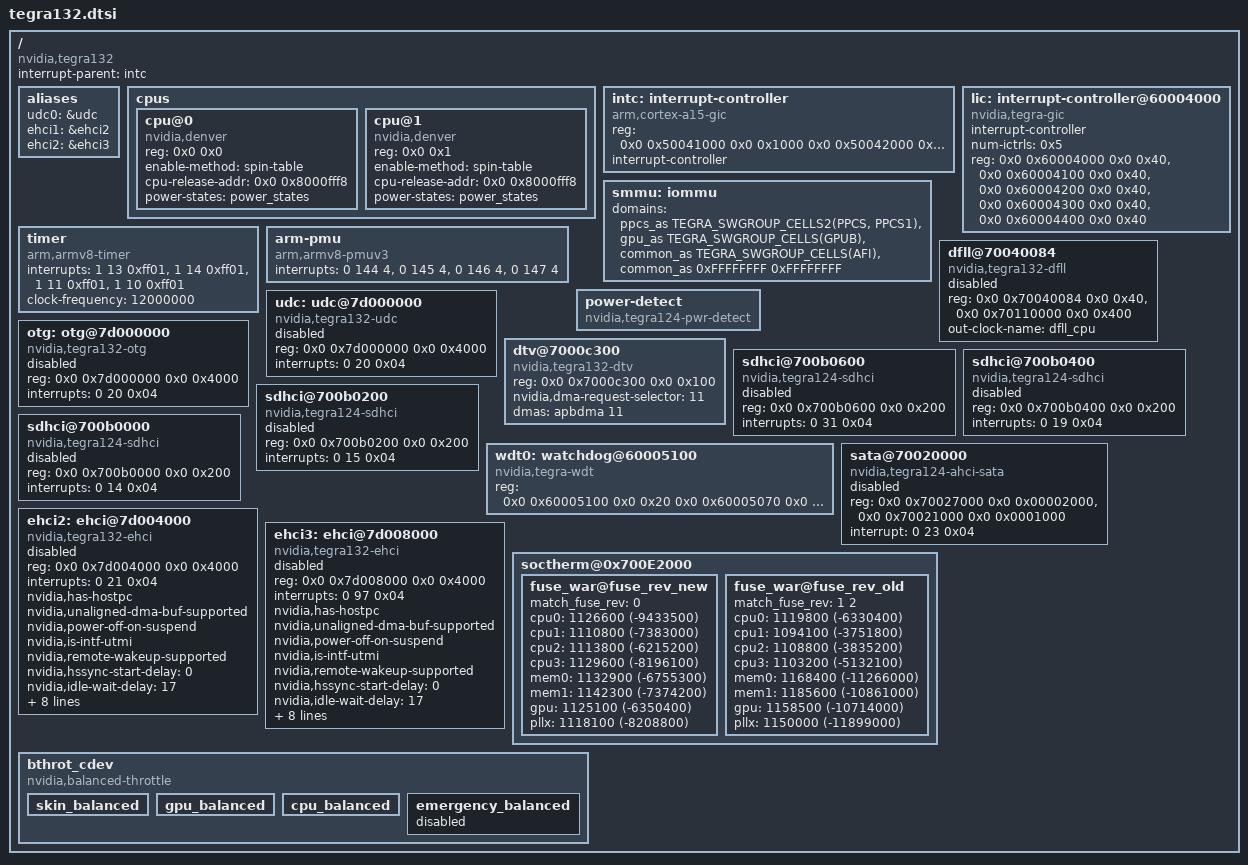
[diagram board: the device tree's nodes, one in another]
/*
 * arch/arm64/boot/dts/tegra132.dtsi
 *
 * Copyright (c) 2013-2014, NVIDIA CORPORATION. All rights reserved.
 *
 * This program is free software; you can redistribute it and/or modify it
 * under the terms and conditions of the GNU General Public License,
 * version 2, as published by the Free Software Foundation.
 *
 * This program is distributed in the hope it will be useful, but WITHOUT
 * ANY WARRANTY; without even the implied warranty of MERCHANTABILITY or
 * FITNESS FOR A PARTICULAR PURPOSE.  See the GNU General Public License for
 * more details.
 *
 * You should have received a copy of the GNU General Public License
 * along with this program.  If not, see <http://www.gnu.org/licenses/>.
 */

#include <dt-bindings/gpio/tegra-gpio.h>
#include <dt-bindings/input/input.h>
#include <dt-bindings/interrupt-controller/arm-gic.h>

#include "denver.dtsi"
#include "tegra124-soc.dtsi"
#include "tegra124-platforms/tegra124-soctherm.dtsi"
#include "tegra124-platforms/tegra124-bthrot-cdev.dtsi"

/ {
	compatible = "nvidia,tegra132";
	interrupt-parent = <&intc>;
	#address-cells = <2>;
	#size-cells = <2>;

	aliases {
		udc0 = &udc;
		ehci1 = &ehci2;
		ehci2 = &ehci3;
	};

	cpus {
		#address-cells = <2>;
		#size-cells = <0>;

		cpu@0 {
			device_type = "cpu";
			compatible = "nvidia,denver", "arm,armv8";
			reg = <0x0 0x0>;
			enable-method = "spin-table";
			cpu-release-addr = <0x0 0x8000fff8>;
			power-states = <&power_states>;
		};

		cpu@1 {
			device_type = "cpu";
			compatible = "nvidia,denver", "arm,armv8";
			reg = <0x0 0x1>;
			enable-method = "spin-table";
			cpu-release-addr = <0x0 0x8000fff8>;
			power-states = <&power_states>;
		};
	};

	intc: interrupt-controller {
		compatible = "arm,cortex-a15-gic";
		reg = <0x0 0x50041000 0x0 0x1000
		       0x0 0x50042000 0x0 0x0100>;
		interrupt-controller;
		#interrupt-cells = <3>;
	};

	lic: interrupt-controller@60004000 {
		compatible = "nvidia,tegra-gic";
		interrupt-controller;
		num-ictrls = <0x5>;
		reg = <0x0 0x60004000 0x0 0x40>,
		      <0x0 0x60004100 0x0 0x40>,
		      <0x0 0x60004200 0x0 0x40>,
		      <0x0 0x60004300 0x0 0x40>,
		      <0x0 0x60004400 0x0 0x40>;
	};

	smmu: iommu {
		domains = <
			&ppcs_as TEGRA_SWGROUP_CELLS2(PPCS, PPCS1)
			&gpu_as TEGRA_SWGROUP_CELLS(GPUB)
			&common_as TEGRA_SWGROUP_CELLS(AFI)
			&common_as 0xFFFFFFFF 0xFFFFFFFF>;
	};

	timer {
		compatible = "arm,armv8-timer";
		interrupts = <1 13 0xff01>,
			     <1 14 0xff01>,
			     <1 11 0xff01>,
			     <1 10 0xff01>;
		clock-frequency = <12000000>;
	};

	arm-pmu {
		compatible = "arm,armv8-pmuv3";
		interrupts = <0 144 4>,
			     <0 145 4>,
			     <0 146 4>,
			     <0 147 4>;
	};

	dfll@70040084 {
		compatible = "nvidia,tegra132-dfll";
		reg = <0x0 0x70040084 0x0 0x40>,
		      <0x0 0x70110000 0x0 0x400>;
		out-clock-name="dfll_cpu";
		status = "disabled";
	};

	power-detect {
		compatible = "nvidia,tegra124-pwr-detect";
	};

	udc: udc@7d000000 {
		compatible = "nvidia,tegra132-udc";
		reg = <0x0 0x7d000000 0x0 0x4000>;
		interrupts = <0 20 0x04>;
		status = "disabled";
	};

	otg: otg@7d000000 {
		compatible = "nvidia,tegra132-otg";
		reg = <0x0 0x7d000000 0x0 0x4000>;
		interrupts = <0 20 0x04>;
		status = "disabled";
	};

	dtv@7000c300 {
		compatible = "nvidia,tegra132-dtv";
		reg = <0x0 0x7000c300 0x0 0x100>;
		nvidia,dma-request-selector = <11>;
		dmas = <&apbdma 11>;
		dma-names = "rx";
		status = "okay";
	};

	sdhci@700b0600 {
		compatible = "nvidia,tegra124-sdhci";
		reg = <0x0 0x700b0600 0x0 0x200>;
		interrupts = < 0 31 0x04 >;
		status = "disabled";
	};

	sdhci@700b0400 {
		compatible = "nvidia,tegra124-sdhci";
		reg = <0x0 0x700b0400 0x0 0x200>;
		interrupts = < 0 19 0x04 >;
		status = "disabled";
	};

	sdhci@700b0200 {
		compatible = "nvidia,tegra124-sdhci";
		reg = <0x0 0x700b0200 0x0 0x200>;
		interrupts = < 0 15 0x04 >;
		status = "disabled";
	};

	sdhci@700b0000 {
		compatible = "nvidia,tegra124-sdhci";
		reg = <0x0 0x700b0000 0x0 0x200>;
		interrupts = < 0 14 0x04 >;
		status = "disabled";
	};
	/* WDT0 using TMR7 as timing reference */
	wdt0: watchdog@60005100 {
		compatible = "nvidia,tegra-wdt";
		reg = <0x0 0x60005100 0x0 0x20		/* WDT0 registers */
			0x0 0x60005070 0x0 0x8>;	/* TMR7 registers */
	};

	sata@70020000 {
		compatible = "nvidia,tegra124-ahci-sata";
		reg = <0x0 0x70027000 0x0 0x00002000>,
			< 0x0 0x70021000 0x0 0x0001000>;
		interrupt = <0 23 0x04>;
		status = "disabled";
	};

	ehci2: ehci@7d004000 {
		compatible = "nvidia,tegra132-ehci";
		reg = <0x0 0x7d004000 0x0 0x4000>;
		interrupts = <0 21 0x04>;
		nvidia,has-hostpc;
		nvidia,unaligned-dma-buf-supported;
		nvidia,power-off-on-suspend;
		nvidia,is-intf-utmi;
		nvidia,remote-wakeup-supported;
		nvidia,hssync-start-delay = <0>;
		nvidia,idle-wait-delay = <17>;
		nvidia,elastic-limit = <16>;
		nvidia,term-range-adj = <6>;
		nvidia,xcvr-setup = <8>;
		nvidia,xcvr-lsfslew = <2>;
		nvidia,xcvr-lsrslew = <2>;
		nvidia,xcvr-use-fuses;
		nvidia,vbus-oc-map = <5>;
		nvidia,xcvr-setup-offset = <0>;
		status = "disabled";
	};

	ehci3: ehci@7d008000 {
		compatible = "nvidia,tegra132-ehci";
		reg = <0x0 0x7d008000 0x0 0x4000>;
		interrupts = <0 97 0x04>;
		nvidia,has-hostpc;
		nvidia,unaligned-dma-buf-supported;
		nvidia,power-off-on-suspend;
		nvidia,is-intf-utmi;
		nvidia,remote-wakeup-supported;
		nvidia,hssync-start-delay = <0>;
		nvidia,idle-wait-delay = <17>;
		nvidia,elastic-limit = <16>;
		nvidia,term-range-adj = <6>;
		nvidia,xcvr-setup = <8>;
		nvidia,xcvr-lsfslew = <2>;
		nvidia,xcvr-lsrslew = <2>;
		nvidia,xcvr-use-fuses;
		nvidia,vbus-oc-map = <5>;
		nvidia,xcvr-setup-offset = <0>;
		status = "disabled";
	};

	soctherm@0x700E2000 {
		fuse_war@fuse_rev_new {
			device_type = "fuse_war";
			match_fuse_rev = <0>; /* see xx_fuse_offsets.h */
			cpu0 = <1126600  (-9433500)>;
			cpu1 = <1110800  (-7383000)>;
			cpu2 = <1113800  (-6215200)>;
			cpu3 = <1129600  (-8196100)>;
			mem0 = <1132900  (-6755300)>;
			mem1 = <1142300  (-7374200)>;
			gpu  = <1125100  (-6350400)>;
			pllx = <1118100  (-8208800)>;
		};
		fuse_war@fuse_rev_old {
			device_type = "fuse_war";
			match_fuse_rev = <1 2>; /* see xx_fuse_offsets.h */
			cpu0 = <1119800   (-6330400)>;
			cpu1 = <1094100   (-3751800)>;
			cpu2 = <1108800   (-3835200)>;
			cpu3 = <1103200   (-5132100)>;
			mem0 = <1168400  (-11266000)>;
			mem1 = <1185600  (-10861000)>;
			gpu  = <1158500  (-10714000)>;
			pllx = <1150000  (-11899000)>;
		};
	};

	bthrot_cdev {
		compatible = "nvidia,balanced-throttle";
		skin_balanced {
			status = "okay";
		};
		gpu_balanced {
			status = "okay";
		};
		cpu_balanced {
			status = "okay";
		};
		emergency_balanced {
			status = "disabled";
		};
	};
};
